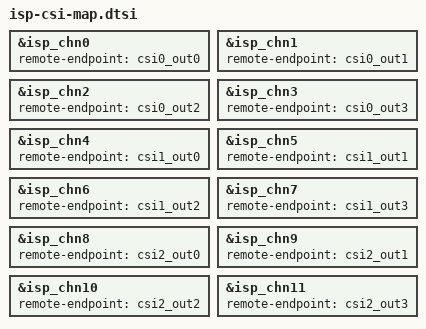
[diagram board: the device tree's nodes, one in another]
&isp_chn0 {
	remote-endpoint = <&csi0_out0>;
};
&isp_chn1 {
	remote-endpoint = <&csi0_out1>;
};
&isp_chn2 {
	remote-endpoint = <&csi0_out2>;
};
&isp_chn3 {
	remote-endpoint = <&csi0_out3>;
};
&isp_chn4 {
	remote-endpoint = <&csi1_out0>;
};
&isp_chn5 {
	remote-endpoint = <&csi1_out1>;
};
&isp_chn6 {
	remote-endpoint = <&csi1_out2>;
};
&isp_chn7 {
	remote-endpoint = <&csi1_out3>;
};
&isp_chn8 {
	remote-endpoint = <&csi2_out0>;
};
&isp_chn9 {
	remote-endpoint = <&csi2_out1>;
};
&isp_chn10 {
	remote-endpoint = <&csi2_out2>;
};
&isp_chn11 {
	remote-endpoint = <&csi2_out3>;
};
